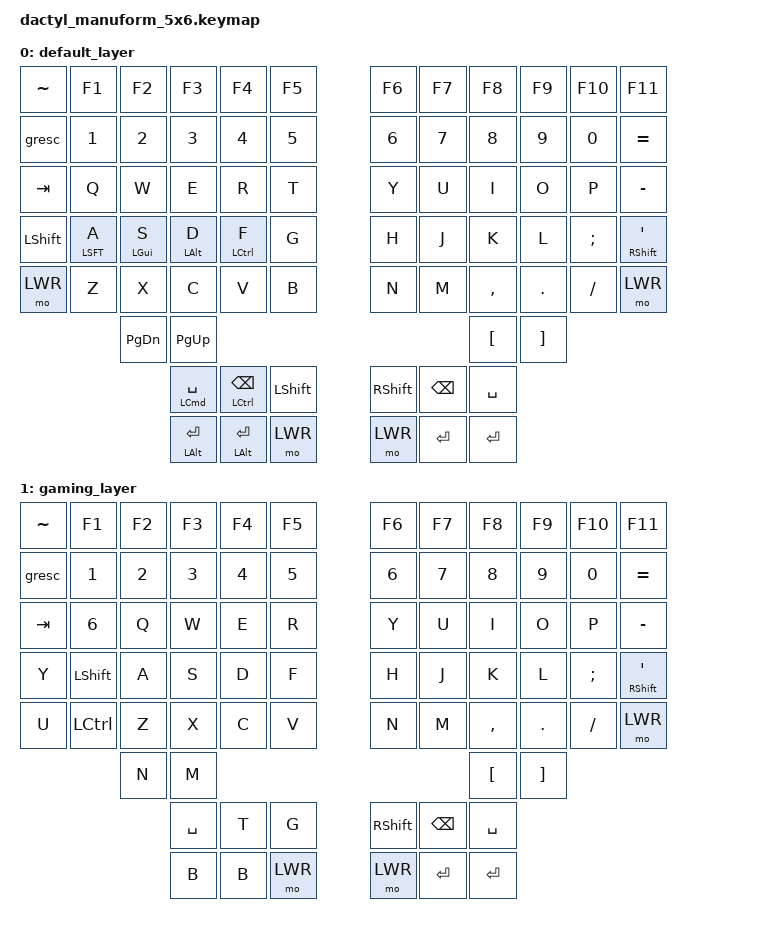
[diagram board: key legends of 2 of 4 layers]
#include <behaviors.dtsi>
#include <dt-bindings/zmk/keys.h>
#include <dt-bindings/zmk/bt.h>
#include <dt-bindings/zmk/outputs.h>
#include <behaviors.dtsi>

#define DEFAULT 0
#define GAM 1
#define LWR 2
#define ADJ 3

&mt {
    tapping-term-ms = <150>;
};

/ {

    keymap {
        compatible = "zmk,keymap";
        default_layer {
            bindings = <
                // position 0     pos 1             pos 2             pos 3             pos 4    pos 5    pos 6    pos 7    pos 8    pos 9    pos 10
                &lh_pht LSFT A    &lh_pht LGUI S    &lh_pht LALT D    &lh_pht LCTL F    &kp G    &kp H    &kp I    &kp J    &kp K    &kp L    &kp SEMI
            >;
        };
    };
};

/ {
    behaviors {
        lh_pht: left_positional_hold_tap {
            compatible = "zmk,behavior-hold-tap";
            #binding-cells = <2>;
            flavor = "tap-unless-interrupted";
            tapping-term-ms = <100>;                        // <---[[produces tap if held longer than tapping-term-ms]]
            quick-tap-ms = <200>;
            bindings = <&kp>, <&kp>;
            hold-trigger-key-positions = <5 6 7 8 9 10>;    // <---[[right-hand keys]]
        };
    };
    keymap {
        compatible = "zmk,keymap";

        default_layer {
            bindings = <
                &kp TILDE &kp F1            &kp F2            &kp F3            &kp F4         &kp F5                       &kp F6      &kp F7     &kp F8    &kp F9   &kp F10  &kp F11
                &gresc    &kp N1            &kp N2            &kp N3            &kp N4         &kp N5                       &kp N6      &kp N7     &kp N8    &kp N9   &kp N0   &kp EQUAL
                &kp TAB   &kp Q             &kp W             &kp E             &kp R          &kp T                        &kp Y       &kp U      &kp I     &kp O    &kp P    &kp MINUS
                &kp LSHFT &lh_pht LSFT A    &lh_pht LGUI S    &lh_pht LALT D    &lh_pht LCTL F &kp G                        &kp H       &kp J      &kp K     &kp L    &kp SEMI &mt RSHFT APOS
                &mo LWR   &kp Z             &kp X             &kp C             &kp V          &kp B                        &kp N       &kp M      &kp COMMA &kp DOT  &kp FSLH &mo LWR
                                            &kp PG_DN         &kp PG_UP                                                                         &kp LBKT  &kp RBKT
                                                              &mt LCMD SPACE    &mt LCTRL BSPC &kp LSHFT                    &kp RSHFT   &kp BSPC   &kp SPACE
                                                              &mt LALT RET      &mt LALT RET   &mo LWR                      &mo LWR     &kp RET    &kp RET
            >;
        };

        gaming_layer {
            bindings = <
                &kp TILDE &kp F1            &kp F2            &kp F3            &kp F4         &kp F5                       &kp F6      &kp F7     &kp F8    &kp F9   &kp F10  &kp F11
                &gresc    &kp N1            &kp N2            &kp N3            &kp N4         &kp N5                       &kp N6      &kp N7     &kp N8    &kp N9   &kp N0   &kp EQUAL
                &kp TAB   &kp N6            &kp Q             &kp W             &kp E          &kp R                        &kp Y       &kp U      &kp I     &kp O    &kp P    &kp MINUS
                &kp Y     &kp LSHFT         &kp A             &kp S             &kp D          &kp F                        &kp H       &kp J      &kp K     &kp L    &kp SEMI &mt RSHFT APOS
                &kp U     &kp LCTRL         &kp Z             &kp X             &kp C          &kp V                        &kp N       &kp M      &kp COMMA &kp DOT  &kp FSLH &mo LWR
                                            &kp N             &kp M                                                                             &kp LBKT  &kp RBKT
                                                              &kp SPACE         &kp T          &kp G                        &kp RSHFT   &kp BSPC   &kp SPACE
                                                              &kp B             &kp B          &mo LWR                      &mo LWR     &kp RET    &kp RET
            >;
        };

        lower_layer {
            bindings = <
                &kp TILDE &kp F1            &kp F2            &kp F3            &kp F4         &kp F5                       &kp F6      &kp F7     &kp F8   &kp F9    &kp F10  &kp F11
                &trans    &kp C_PP          &kp C_PREV        &kp C_NEXT        &trans         &trans                       &trans      &trans     &trans   &kp F11   &kp F12  &kp BSLH
                &trans    &kp C_MUTE        &kp C_VOL_DN      &kp C_VOL_UP      &trans         &tog GAM                     &kp LEFT    &kp DOWN   &kp UP   &kp RIGHT &trans   &trans
                &trans    &trans            &kp F14           &kp F15           &trans         &trans                       &trans      &trans     &trans   &trans    &trans   &trans
                                            &kp END           &kp HOME                                                                         &trans   &trans
                                                              &mo ADJ           &trans         &trans                       &trans      &kp DEL    &mo ADJ
                                                              &trans            &trans         &trans                       &trans      &trans     &trans
            >;
        };

        adjust_layer {
            bindings = <
                &none    &bt BT_SEL 0       &bt BT_SEL 1      &bt BT_SEL 2      &bt BT_SEL 3   &bt BT_SEL 4                 &none       &none      &none    &none     &none    &none
                &none    &none              &out OUT_BLE      &none             &sys_reset     &none                        &none       &sys_reset &none    &none     &none    &none
                &none    &none              &out OUT_USB      &none             &none          &none                        &none       &none      &none    &none     &none    &none
                &tog GAM &none              &none             &bt BT_CLR        &none          &bootloader                  &bootloader &none      &none    &none     &none    &none
                                            &none             &none                                                                            &none    &none
                                                              &none             &none          &none                        &none       &none      &none
                                                              &none             &none          &none                        &none       &none      &none
            >;
        };
    };
};
